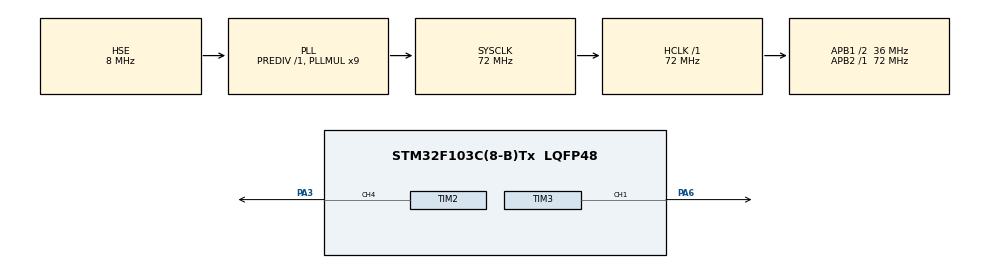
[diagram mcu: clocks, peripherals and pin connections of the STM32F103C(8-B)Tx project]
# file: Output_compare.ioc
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Mcu.Family=STM32F1
Mcu.Name=STM32F103C(8-B)Tx
Mcu.Package=LQFP48
NVIC.PriorityGroup=NVIC_PRIORITYGROUP_4
PA13.Mode=Serial_Wire
PA13.Signal=SYS_JTMS-SWDIO
PA14.Mode=Serial_Wire
PA14.Signal=SYS_JTCK-SWCLK
PA3.Signal=S_TIM2_CH4
PA6.Signal=S_TIM3_CH1
PD0-OSC_IN.Mode=HSE-External-Oscillator
PD0-OSC_IN.Signal=RCC_OSC_IN
PD1-OSC_OUT.Mode=HSE-External-Oscillator
PD1-OSC_OUT.Signal=RCC_OSC_OUT
ProjectManager.HeapSize=0x200
ProjectManager.StackSize=0x400
ProjectManager.TargetToolchain=MDK-ARM V5.27
RCC.AHBFreq_Value=72000000
RCC.APB1CLKDivider=RCC_HCLK_DIV2
RCC.APB1Freq_Value=36000000
RCC.APB1TimFreq_Value=72000000
RCC.APB2Freq_Value=72000000
RCC.APB2TimFreq_Value=72000000
RCC.HCLKFreq_Value=72000000
RCC.PLLMUL=RCC_PLL_MUL9
RCC.PLLSourceVirtual=RCC_PLLSOURCE_HSE
RCC.SYSCLKFreq_VALUE=72000000
RCC.SYSCLKSource=RCC_SYSCLKSOURCE_PLLCLK
RCC.USBFreq_Value=72000000
SH.S_TIM2_CH4.0=TIM2_CH4,Output Compare4 CH4
SH.S_TIM3_CH1.0=TIM3_CH1,Output Compare1 CH1
TIM2.Channel-Output\ Compare4\ CH4=TIM_CHANNEL_4
TIM2.OCMode_4=TIM_OCMODE_TOGGLE
TIM2.Period=999
TIM2.Prescaler=7199
TIM2.Pulse-Output\ Compare4\ CH4=799
TIM3.Channel-Output\ Compare1\ CH1=TIM_CHANNEL_1
TIM3.OC1Preload=ENABLE
TIM3.OCMode_1=TIM_OCMODE_FORCED_ACTIVE
TIM3.OCPolarity_1=TIM_OCPOLARITY_LOW
TIM3.Period=999
TIM3.Prescaler=719
TIM3.Pulse-Output\ Compare1\ CH1=299
TIM3.TIM_MasterOutputTrigger=TIM_TRGO_RESET
VP_TIM2_VS_ClockSourceINT.Mode=Internal
VP_TIM3_VS_ClockSourceINT.Mode=Internal
board=custom

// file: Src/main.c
/* USER CODE BEGIN Header */
/**
  ******************************************************************************
  * @file           : main.c
  * @brief          : Main program body
  ******************************************************************************
  * @attention
  *
  * <h2><center>&copy; Copyright (c) 2020 STMicroelectronics.
  * All rights reserved.</center></h2>
  *
  * This software component is licensed by ST under BSD 3-Clause license,
  * the "License"; You may not use this file except in compliance with the
  * License. You may obtain a copy of the License at:
  *                        opensource.org/licenses/BSD-3-Clause
  *
  ******************************************************************************
  */
/* USER CODE END Header */

#include "main.h"

TIM_HandleTypeDef htim2;
TIM_HandleTypeDef htim3;

void SystemClock_Config(void);
static void MX_GPIO_Init(void);
static void MX_TIM2_Init(void);
static void MX_TIM3_Init(void);

int main(void)
{

  /* MCU Configuration--------------------------------------------------------*/

  /* Reset of all peripherals, Initializes the Flash interface and the Systick. */
  HAL_Init();

  /* Configure the system clock */
  SystemClock_Config();

  /* Initialize all configured peripherals */
  MX_GPIO_Init();
  MX_TIM2_Init();
  MX_TIM3_Init();
  /* USER CODE BEGIN 2 */
	HAL_TIM_OC_Start(&htim2,TIM_CHANNEL_4);
	HAL_TIM_OC_Start(&htim3,TIM_CHANNEL_1);
  /* USER CODE END 2 */

  /* Infinite loop */
  while (1)
  {

  }
}

void SystemClock_Config(void)
{
  RCC_OscInitTypeDef RCC_OscInitStruct = {0};
  RCC_ClkInitTypeDef RCC_ClkInitStruct = {0};

  /** Initializes the CPU, AHB and APB busses clocks
  */
  RCC_OscInitStruct.OscillatorType = RCC_OSCILLATORTYPE_HSE;
  RCC_OscInitStruct.HSEState = RCC_HSE_ON;
  RCC_OscInitStruct.HSEPredivValue = RCC_HSE_PREDIV_DIV1;
  RCC_OscInitStruct.HSIState = RCC_HSI_ON;
  RCC_OscInitStruct.PLL.PLLState = RCC_PLL_ON;
  RCC_OscInitStruct.PLL.PLLSource = RCC_PLLSOURCE_HSE;
  RCC_OscInitStruct.PLL.PLLMUL = RCC_PLL_MUL9;
  if (HAL_RCC_OscConfig(&RCC_OscInitStruct) != HAL_OK)
  {
    Error_Handler();
  }
  /** Initializes the CPU, AHB and APB busses clocks
  */
  RCC_ClkInitStruct.ClockType = RCC_CLOCKTYPE_HCLK|RCC_CLOCKTYPE_SYSCLK
                              |RCC_CLOCKTYPE_PCLK1|RCC_CLOCKTYPE_PCLK2;
  RCC_ClkInitStruct.SYSCLKSource = RCC_SYSCLKSOURCE_PLLCLK;
  RCC_ClkInitStruct.AHBCLKDivider = RCC_SYSCLK_DIV1;
  RCC_ClkInitStruct.APB1CLKDivider = RCC_HCLK_DIV2;
  RCC_ClkInitStruct.APB2CLKDivider = RCC_HCLK_DIV1;

  if (HAL_RCC_ClockConfig(&RCC_ClkInitStruct, FLASH_LATENCY_2) != HAL_OK)
  {
    Error_Handler();
  }
}

static void MX_TIM2_Init(void)
{

  TIM_ClockConfigTypeDef sClockSourceConfig = {0};
  TIM_MasterConfigTypeDef sMasterConfig = {0};
  TIM_OC_InitTypeDef sConfigOC = {0};

  htim2.Instance = TIM2;
  htim2.Init.Prescaler = 7199;
  htim2.Init.CounterMode = TIM_COUNTERMODE_UP;
  htim2.Init.Period = 999;
  htim2.Init.ClockDivision = TIM_CLOCKDIVISION_DIV1;
  htim2.Init.AutoReloadPreload = TIM_AUTORELOAD_PRELOAD_DISABLE;
  if (HAL_TIM_Base_Init(&htim2) != HAL_OK)
  {
    Error_Handler();
  }
  sClockSourceConfig.ClockSource = TIM_CLOCKSOURCE_INTERNAL;
  if (HAL_TIM_ConfigClockSource(&htim2, &sClockSourceConfig) != HAL_OK)
  {
    Error_Handler();
  }
  if (HAL_TIM_OC_Init(&htim2) != HAL_OK)
  {
    Error_Handler();
  }
  sMasterConfig.MasterOutputTrigger = TIM_TRGO_RESET;
  sMasterConfig.MasterSlaveMode = TIM_MASTERSLAVEMODE_DISABLE;
  if (HAL_TIMEx_MasterConfigSynchronization(&htim2, &sMasterConfig) != HAL_OK)
  {
    Error_Handler();
  }
  sConfigOC.OCMode = TIM_OCMODE_TOGGLE;
  sConfigOC.Pulse = 799;
  sConfigOC.OCPolarity = TIM_OCPOLARITY_HIGH;
  sConfigOC.OCFastMode = TIM_OCFAST_DISABLE;
  if (HAL_TIM_OC_ConfigChannel(&htim2, &sConfigOC, TIM_CHANNEL_4) != HAL_OK)
  {
    Error_Handler();
  }
  HAL_TIM_MspPostInit(&htim2);

}

static void MX_TIM3_Init(void)
{

  TIM_ClockConfigTypeDef sClockSourceConfig = {0};
  TIM_MasterConfigTypeDef sMasterConfig = {0};
  TIM_OC_InitTypeDef sConfigOC = {0};

  htim3.Instance = TIM3;
  htim3.Init.Prescaler = 719;
  htim3.Init.CounterMode = TIM_COUNTERMODE_UP;
  htim3.Init.Period = 999;
  htim3.Init.ClockDivision = TIM_CLOCKDIVISION_DIV1;
  htim3.Init.AutoReloadPreload = TIM_AUTORELOAD_PRELOAD_DISABLE;
  if (HAL_TIM_Base_Init(&htim3) != HAL_OK)
  {
    Error_Handler();
  }
  sClockSourceConfig.ClockSource = TIM_CLOCKSOURCE_INTERNAL;
  if (HAL_TIM_ConfigClockSource(&htim3, &sClockSourceConfig) != HAL_OK)
  {
    Error_Handler();
  }
  if (HAL_TIM_OC_Init(&htim3) != HAL_OK)
  {
    Error_Handler();
  }
  sMasterConfig.MasterOutputTrigger = TIM_TRGO_RESET;
  sMasterConfig.MasterSlaveMode = TIM_MASTERSLAVEMODE_DISABLE;
  if (HAL_TIMEx_MasterConfigSynchronization(&htim3, &sMasterConfig) != HAL_OK)
  {
    Error_Handler();
  }
  sConfigOC.OCMode = TIM_OCMODE_FORCED_ACTIVE;
  sConfigOC.Pulse = 299;
  sConfigOC.OCPolarity = TIM_OCPOLARITY_LOW;
  sConfigOC.OCFastMode = TIM_OCFAST_DISABLE;
  if (HAL_TIM_OC_ConfigChannel(&htim3, &sConfigOC, TIM_CHANNEL_1) != HAL_OK)
  {
    Error_Handler();
  }
  __HAL_TIM_ENABLE_OCxPRELOAD(&htim3, TIM_CHANNEL_1);
  HAL_TIM_MspPostInit(&htim3);

}

static void MX_GPIO_Init(void)
{

  /* GPIO Ports Clock Enable */
  __HAL_RCC_GPIOD_CLK_ENABLE();
  __HAL_RCC_GPIOA_CLK_ENABLE();

}

void Error_Handler(void)
{
}

/************************ (C) COPYRIGHT STMicroelectronics *****END OF FILE****/
